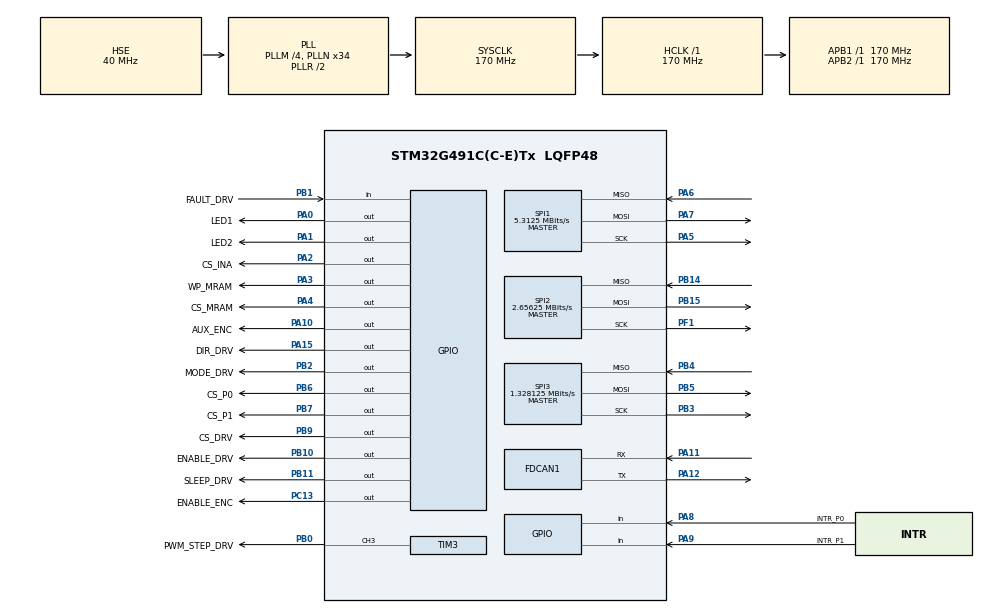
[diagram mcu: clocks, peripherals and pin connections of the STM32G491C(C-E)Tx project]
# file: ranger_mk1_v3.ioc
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FDCAN1.AutoRetransmission=ENABLE
FDCAN1.CalculateBaudRateNominal=1000000
FDCAN1.CalculateTimeBitNominal=1000
FDCAN1.CalculateTimeQuantumNominal=100.0
FDCAN1.ExtFiltersNbr=1
FDCAN1.NominalPrescaler=17
FDCAN1.NominalSyncJumpWidth=2
FDCAN1.NominalTimeSeg1=7
FDCAN1.NominalTimeSeg2=2
Mcu.Family=STM32G4
Mcu.Name=STM32G491C(C-E)Tx
Mcu.Package=LQFP48
NVIC.PriorityGroup=NVIC_PRIORITYGROUP_4
NVIC.TIM2_IRQn=true\:0\:0\:false\:false\:true\:true\:true\:true
PA0.GPIO_Label=LED1
PA0.PinState=GPIO_PIN_SET
PA0.Signal=GPIO_Output
PA1.GPIO_Label=LED2
PA1.PinState=GPIO_PIN_SET
PA1.Signal=GPIO_Output
PA10.GPIO_Label=AUX_ENC
PA10.Signal=GPIO_Output
PA11.Mode=FDCAN_Activate
PA11.Signal=FDCAN1_RX
PA12.Mode=FDCAN_Activate
PA12.Signal=FDCAN1_TX
PA13.Mode=Serial_Wire
PA13.Signal=SYS_JTMS-SWDIO
PA14.Mode=Serial_Wire
PA14.Signal=SYS_JTCK-SWCLK
PA15.GPIO_Label=DIR_DRV
PA15.PinState=GPIO_PIN_RESET
PA15.Signal=GPIO_Output
PA2.GPIO_Label=CS_INA
PA2.PinState=GPIO_PIN_SET
PA2.Signal=GPIO_Output
PA3.GPIO_Label=WP_MRAM
PA3.PinState=GPIO_PIN_SET
PA3.Signal=GPIO_Output
PA4.GPIO_Label=CS_MRAM
PA4.PinState=GPIO_PIN_SET
PA4.Signal=GPIO_Output
PA5.Mode=Full_Duplex_Master
PA5.Signal=SPI1_SCK
PA6.Mode=Full_Duplex_Master
PA6.Signal=SPI1_MISO
PA7.Mode=Full_Duplex_Master
PA7.Signal=SPI1_MOSI
PA8.GPIO_Label=INTR_P0
PA8.Signal=GPIO_Input
PA9.GPIO_Label=INTR_P1
PA9.Signal=GPIO_Input
PB0.GPIO_Label=PWM_STEP_DRV
PB0.Signal=S_TIM3_CH3
PB1.GPIO_Label=FAULT_DRV
PB1.Signal=GPIO_Input
PB10.GPIO_Label=ENABLE_DRV
PB10.Signal=GPIO_Output
PB11.GPIO_Label=SLEEP_DRV
PB11.Signal=GPIO_Output
PB14.Mode=Full_Duplex_Master
PB14.Signal=SPI2_MISO
PB15.Mode=Full_Duplex_Master
PB15.Signal=SPI2_MOSI
PB2.GPIO_Label=MODE_DRV
PB2.PinState=GPIO_PIN_SET
PB2.Signal=GPIO_Output
PB3.Mode=Full_Duplex_Master
PB3.Signal=SPI3_SCK
PB4.Mode=Full_Duplex_Master
PB4.Signal=SPI3_MISO
PB5.Mode=Full_Duplex_Master
PB5.Signal=SPI3_MOSI
PB6.GPIO_Label=CS_P0
PB6.PinState=GPIO_PIN_SET
PB6.Signal=GPIO_Output
PB7.GPIO_Label=CS_P1
PB7.PinState=GPIO_PIN_SET
PB7.Signal=GPIO_Output
PB9.GPIO_Label=CS_DRV
PB9.PinState=GPIO_PIN_SET
PB9.Signal=GPIO_Output
PC13.GPIO_Label=ENABLE_ENC
PC13.PinState=GPIO_PIN_SET
PC13.Signal=GPIO_Output
PF0-OSC_IN.Mode=HSE-External-Clock-Source
PF0-OSC_IN.Signal=RCC_OSC_IN
PF1-OSC_OUT.Mode=Full_Duplex_Master
PF1-OSC_OUT.Signal=SPI2_SCK
ProjectManager.HeapSize=0x200
ProjectManager.StackSize=0x400
ProjectManager.TargetToolchain=STM32CubeIDE
RCC.ADC12Freq_Value=170000000
RCC.ADC345Freq_Value=170000000
RCC.AHBFreq_Value=170000000
RCC.APB1Freq_Value=170000000
RCC.APB1TimFreq_Value=170000000
RCC.APB2Freq_Value=170000000
RCC.APB2TimFreq_Value=170000000
RCC.CortexFreq_Value=170000000
RCC.EXTERNAL_CLOCK_VALUE=12288000
RCC.HCLKFreq_Value=170000000
RCC.HSE_VALUE=40000000
RCC.HSI48_VALUE=48000000
RCC.HSI_VALUE=16000000
RCC.LSE_VALUE=32768
RCC.PLLM=RCC_PLLM_DIV4
RCC.PLLN=34
RCC.PLLSourceVirtual=RCC_PLLSOURCE_HSE
RCC.SYSCLKFreq_VALUE=170000000
RCC.SYSCLKSource=RCC_SYSCLKSOURCE_PLLCLK
RCC.VCOOutputFreq_Value=340000000
SH.S_TIM3_CH3.0=TIM3_CH3,PWM Generation3 CH3
SPI1.BaudRatePrescaler=SPI_BAUDRATEPRESCALER_32
SPI1.CalculateBaudRate=5.3125 MBits/s
SPI1.DataSize=SPI_DATASIZE_8BIT
SPI1.Direction=SPI_DIRECTION_2LINES
SPI1.Mode=SPI_MODE_MASTER
SPI1.VirtualType=VM_MASTER
SPI2.BaudRatePrescaler=SPI_BAUDRATEPRESCALER_64
SPI2.CLKPhase=SPI_PHASE_2EDGE
SPI2.CalculateBaudRate=2.65625 MBits/s
SPI2.DataSize=SPI_DATASIZE_8BIT
SPI2.Direction=SPI_DIRECTION_2LINES
SPI2.Mode=SPI_MODE_MASTER
SPI2.VirtualType=VM_MASTER
SPI3.BaudRatePrescaler=SPI_BAUDRATEPRESCALER_128
SPI3.CLKPhase=SPI_PHASE_2EDGE
SPI3.CalculateBaudRate=1.328125 MBits/s
SPI3.DataSize=SPI_DATASIZE_8BIT
SPI3.Direction=SPI_DIRECTION_2LINES
SPI3.Mode=SPI_MODE_MASTER
SPI3.VirtualType=VM_MASTER
TIM2.PeriodNoDither=4294967295
TIM2.Prescaler=0
TIM2.TIM_MasterOutputTrigger=TIM_TRGO_RESET
TIM3.AutoReloadPreload=TIM_AUTORELOAD_PRELOAD_ENABLE
TIM3.Channel-PWM\ Generation3\ CH3=TIM_CHANNEL_3
TIM3.OC3Preload_PWM=DISABLE
TIM3.PeriodNoDither=999
TIM3.Prescaler=169
TIM3.PulseNoDither_3=2
TIM3.TIM_MasterOutputTrigger=TIM_TRGO_OC3REF
VP_SYS_VS_DBSignals.Mode=DisableDeadBatterySignals
VP_TIM2_VS_ClockSourceITR.Mode=TriggerSource_ITR2
VP_TIM2_VS_ControllerModeClock.Mode=Clock Mode
VP_TIM3_VS_ClockSourceINT.Mode=Internal
board=custom

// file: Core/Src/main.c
/* USER CODE BEGIN Header */
/**
  ******************************************************************************
  * @file           : main.c
  * @brief          : Main program body
  ******************************************************************************
  */
/* USER CODE END Header */
#include "main.h"

/* USER CODE BEGIN Includes */
#include "ranger_app.h"
/* USER CODE END Includes */

FDCAN_HandleTypeDef hfdcan1;

SPI_HandleTypeDef hspi1;
SPI_HandleTypeDef hspi2;
SPI_HandleTypeDef hspi3;

TIM_HandleTypeDef htim2;
TIM_HandleTypeDef htim3;

void SystemClock_Config(void);
static void MX_GPIO_Init(void);
static void MX_FDCAN1_Init(void);
static void MX_SPI1_Init(void);
static void MX_SPI2_Init(void);
static void MX_TIM2_Init(void);
static void MX_TIM3_Init(void);
static void MX_SPI3_Init(void);

int main(void)
{

  /* USER CODE BEGIN 1 */
  SCB->VTOR = 0x08008000U;
  /* USER CODE END 1 */

  /* MCU Configuration--------------------------------------------------------*/

  /* Reset of all peripherals, Initializes the Flash interface and the Systick. */
  HAL_Init();

  /* Configure the system clock */
  SystemClock_Config();

  /* Initialize all configured peripherals */
  MX_GPIO_Init();
  MX_FDCAN1_Init();
  MX_SPI1_Init();
  MX_SPI2_Init();
  MX_TIM2_Init();
  MX_TIM3_Init();
  MX_SPI3_Init();
  /* USER CODE BEGIN 2 */
  HAL_Delay(100);
  ranger_app_init();
  /* USER CODE END 2 */

  /* Infinite loop */
  while (1)
  {

    /* USER CODE BEGIN 3 */
	ranger_app_tick();

  }
  /* USER CODE END 3 */
}

void SystemClock_Config(void)
{
  RCC_OscInitTypeDef RCC_OscInitStruct = {0};
  RCC_ClkInitTypeDef RCC_ClkInitStruct = {0};

  /** Configure the main internal regulator output voltage
  */
  HAL_PWREx_ControlVoltageScaling(PWR_REGULATOR_VOLTAGE_SCALE1_BOOST);

  /** Initializes the RCC Oscillators according to the specified parameters
  * in the RCC_OscInitTypeDef structure.
  */
  RCC_OscInitStruct.OscillatorType = RCC_OSCILLATORTYPE_HSE;
  RCC_OscInitStruct.HSEState = RCC_HSE_BYPASS;
  RCC_OscInitStruct.PLL.PLLState = RCC_PLL_ON;
  RCC_OscInitStruct.PLL.PLLSource = RCC_PLLSOURCE_HSE;
  RCC_OscInitStruct.PLL.PLLM = RCC_PLLM_DIV4;
  RCC_OscInitStruct.PLL.PLLN = 34;
  RCC_OscInitStruct.PLL.PLLP = RCC_PLLP_DIV2;
  RCC_OscInitStruct.PLL.PLLQ = RCC_PLLQ_DIV2;
  RCC_OscInitStruct.PLL.PLLR = RCC_PLLR_DIV2;
  if (HAL_RCC_OscConfig(&RCC_OscInitStruct) != HAL_OK)
  {
    Error_Handler();
  }

  /** Initializes the CPU, AHB and APB buses clocks
  */
  RCC_ClkInitStruct.ClockType = RCC_CLOCKTYPE_HCLK|RCC_CLOCKTYPE_SYSCLK
                              |RCC_CLOCKTYPE_PCLK1|RCC_CLOCKTYPE_PCLK2;
  RCC_ClkInitStruct.SYSCLKSource = RCC_SYSCLKSOURCE_PLLCLK;
  RCC_ClkInitStruct.AHBCLKDivider = RCC_SYSCLK_DIV1;
  RCC_ClkInitStruct.APB1CLKDivider = RCC_HCLK_DIV1;
  RCC_ClkInitStruct.APB2CLKDivider = RCC_HCLK_DIV1;

  if (HAL_RCC_ClockConfig(&RCC_ClkInitStruct, FLASH_LATENCY_4) != HAL_OK)
  {
    Error_Handler();
  }
}

static void MX_FDCAN1_Init(void)
{

  hfdcan1.Instance = FDCAN1;
  hfdcan1.Init.ClockDivider = FDCAN_CLOCK_DIV1;
  hfdcan1.Init.FrameFormat = FDCAN_FRAME_CLASSIC;
  hfdcan1.Init.Mode = FDCAN_MODE_NORMAL;
  hfdcan1.Init.AutoRetransmission = ENABLE;
  hfdcan1.Init.TransmitPause = DISABLE;
  hfdcan1.Init.ProtocolException = DISABLE;
  hfdcan1.Init.NominalPrescaler = 17;
  hfdcan1.Init.NominalSyncJumpWidth = 2;
  hfdcan1.Init.NominalTimeSeg1 = 7;
  hfdcan1.Init.NominalTimeSeg2 = 2;
  hfdcan1.Init.DataPrescaler = 1;
  hfdcan1.Init.DataSyncJumpWidth = 1;
  hfdcan1.Init.DataTimeSeg1 = 1;
  hfdcan1.Init.DataTimeSeg2 = 1;
  hfdcan1.Init.StdFiltersNbr = 0;
  hfdcan1.Init.ExtFiltersNbr = 1;
  hfdcan1.Init.TxFifoQueueMode = FDCAN_TX_FIFO_OPERATION;
  if (HAL_FDCAN_Init(&hfdcan1) != HAL_OK)
  {
    Error_Handler();
  }

}

static void MX_SPI1_Init(void)
{

  /* SPI1 parameter configuration*/
  hspi1.Instance = SPI1;
  hspi1.Init.Mode = SPI_MODE_MASTER;
  hspi1.Init.Direction = SPI_DIRECTION_2LINES;
  hspi1.Init.DataSize = SPI_DATASIZE_8BIT;
  hspi1.Init.CLKPolarity = SPI_POLARITY_LOW;
  hspi1.Init.CLKPhase = SPI_PHASE_1EDGE;
  hspi1.Init.NSS = SPI_NSS_SOFT;
  hspi1.Init.BaudRatePrescaler = SPI_BAUDRATEPRESCALER_32;
  hspi1.Init.FirstBit = SPI_FIRSTBIT_MSB;
  hspi1.Init.TIMode = SPI_TIMODE_DISABLE;
  hspi1.Init.CRCCalculation = SPI_CRCCALCULATION_DISABLE;
  hspi1.Init.CRCPolynomial = 7;
  hspi1.Init.CRCLength = SPI_CRC_LENGTH_DATASIZE;
  hspi1.Init.NSSPMode = SPI_NSS_PULSE_ENABLE;
  if (HAL_SPI_Init(&hspi1) != HAL_OK)
  {
    Error_Handler();
  }

}

static void MX_SPI2_Init(void)
{

  /* SPI2 parameter configuration*/
  hspi2.Instance = SPI2;
  hspi2.Init.Mode = SPI_MODE_MASTER;
  hspi2.Init.Direction = SPI_DIRECTION_2LINES;
  hspi2.Init.DataSize = SPI_DATASIZE_8BIT;
  hspi2.Init.CLKPolarity = SPI_POLARITY_LOW;
  hspi2.Init.CLKPhase = SPI_PHASE_2EDGE;
  hspi2.Init.NSS = SPI_NSS_SOFT;
  hspi2.Init.BaudRatePrescaler = SPI_BAUDRATEPRESCALER_64;
  hspi2.Init.FirstBit = SPI_FIRSTBIT_MSB;
  hspi2.Init.TIMode = SPI_TIMODE_DISABLE;
  hspi2.Init.CRCCalculation = SPI_CRCCALCULATION_DISABLE;
  hspi2.Init.CRCPolynomial = 7;
  hspi2.Init.CRCLength = SPI_CRC_LENGTH_DATASIZE;
  hspi2.Init.NSSPMode = SPI_NSS_PULSE_DISABLE;
  if (HAL_SPI_Init(&hspi2) != HAL_OK)
  {
    Error_Handler();
  }

}

static void MX_SPI3_Init(void)
{

  /* SPI3 parameter configuration*/
  hspi3.Instance = SPI3;
  hspi3.Init.Mode = SPI_MODE_MASTER;
  hspi3.Init.Direction = SPI_DIRECTION_2LINES;
  hspi3.Init.DataSize = SPI_DATASIZE_8BIT;
  hspi3.Init.CLKPolarity = SPI_POLARITY_LOW;
  hspi3.Init.CLKPhase = SPI_PHASE_2EDGE;
  hspi3.Init.NSS = SPI_NSS_SOFT;
  hspi3.Init.BaudRatePrescaler = SPI_BAUDRATEPRESCALER_128;
  hspi3.Init.FirstBit = SPI_FIRSTBIT_MSB;
  hspi3.Init.TIMode = SPI_TIMODE_DISABLE;
  hspi3.Init.CRCCalculation = SPI_CRCCALCULATION_DISABLE;
  hspi3.Init.CRCPolynomial = 7;
  hspi3.Init.CRCLength = SPI_CRC_LENGTH_DATASIZE;
  hspi3.Init.NSSPMode = SPI_NSS_PULSE_DISABLE;
  if (HAL_SPI_Init(&hspi3) != HAL_OK)
  {
    Error_Handler();
  }

}

static void MX_TIM2_Init(void)
{

  TIM_SlaveConfigTypeDef sSlaveConfig = {0};
  TIM_MasterConfigTypeDef sMasterConfig = {0};

  htim2.Instance = TIM2;
  htim2.Init.Prescaler = 0;
  htim2.Init.CounterMode = TIM_COUNTERMODE_UP;
  htim2.Init.Period = 4294967295;
  htim2.Init.ClockDivision = TIM_CLOCKDIVISION_DIV1;
  htim2.Init.AutoReloadPreload = TIM_AUTORELOAD_PRELOAD_DISABLE;
  if (HAL_TIM_Base_Init(&htim2) != HAL_OK)
  {
    Error_Handler();
  }
  sSlaveConfig.SlaveMode = TIM_SLAVEMODE_EXTERNAL1;
  sSlaveConfig.InputTrigger = TIM_TS_ITR2;
  if (HAL_TIM_SlaveConfigSynchro(&htim2, &sSlaveConfig) != HAL_OK)
  {
    Error_Handler();
  }
  sMasterConfig.MasterOutputTrigger = TIM_TRGO_RESET;
  sMasterConfig.MasterSlaveMode = TIM_MASTERSLAVEMODE_DISABLE;
  if (HAL_TIMEx_MasterConfigSynchronization(&htim2, &sMasterConfig) != HAL_OK)
  {
    Error_Handler();
  }

}

static void MX_TIM3_Init(void)
{

  TIM_ClockConfigTypeDef sClockSourceConfig = {0};
  TIM_MasterConfigTypeDef sMasterConfig = {0};
  TIM_OC_InitTypeDef sConfigOC = {0};

  htim3.Instance = TIM3;
  htim3.Init.Prescaler = 169;
  htim3.Init.CounterMode = TIM_COUNTERMODE_UP;
  htim3.Init.Period = 999;
  htim3.Init.ClockDivision = TIM_CLOCKDIVISION_DIV1;
  htim3.Init.AutoReloadPreload = TIM_AUTORELOAD_PRELOAD_ENABLE;
  if (HAL_TIM_Base_Init(&htim3) != HAL_OK)
  {
    Error_Handler();
  }
  sClockSourceConfig.ClockSource = TIM_CLOCKSOURCE_INTERNAL;
  if (HAL_TIM_ConfigClockSource(&htim3, &sClockSourceConfig) != HAL_OK)
  {
    Error_Handler();
  }
  if (HAL_TIM_PWM_Init(&htim3) != HAL_OK)
  {
    Error_Handler();
  }
  sMasterConfig.MasterOutputTrigger = TIM_TRGO_OC3REF;
  sMasterConfig.MasterSlaveMode = TIM_MASTERSLAVEMODE_DISABLE;
  if (HAL_TIMEx_MasterConfigSynchronization(&htim3, &sMasterConfig) != HAL_OK)
  {
    Error_Handler();
  }
  sConfigOC.OCMode = TIM_OCMODE_PWM1;
  sConfigOC.Pulse = 2;
  sConfigOC.OCPolarity = TIM_OCPOLARITY_HIGH;
  sConfigOC.OCFastMode = TIM_OCFAST_DISABLE;
  if (HAL_TIM_PWM_ConfigChannel(&htim3, &sConfigOC, TIM_CHANNEL_3) != HAL_OK)
  {
    Error_Handler();
  }
  __HAL_TIM_DISABLE_OCxPRELOAD(&htim3, TIM_CHANNEL_3);
  HAL_TIM_MspPostInit(&htim3);

}

static void MX_GPIO_Init(void)
{
  GPIO_InitTypeDef GPIO_InitStruct = {0};

  /* GPIO Ports Clock Enable */
  __HAL_RCC_GPIOC_CLK_ENABLE();
  __HAL_RCC_GPIOF_CLK_ENABLE();
  __HAL_RCC_GPIOA_CLK_ENABLE();
  __HAL_RCC_GPIOB_CLK_ENABLE();

  /*Configure GPIO pin Output Level */
  HAL_GPIO_WritePin(ENABLE_ENC_GPIO_Port, ENABLE_ENC_Pin, GPIO_PIN_SET);

  /*Configure GPIO pin Output Level */
  HAL_GPIO_WritePin(GPIOA, LED1_Pin|LED2_Pin|CS_INA_Pin|WP_MRAM_Pin
                          |CS_MRAM_Pin, GPIO_PIN_SET);

  /*Configure GPIO pin Output Level */
  HAL_GPIO_WritePin(GPIOB, MODE_DRV_Pin|CS_P0_Pin|CS_P1_Pin|CS_DRV_Pin, GPIO_PIN_SET);

  /*Configure GPIO pin Output Level */
  HAL_GPIO_WritePin(GPIOB, ENABLE_DRV_Pin|SLEEP_DRV_Pin, GPIO_PIN_RESET);

  /*Configure GPIO pin Output Level */
  HAL_GPIO_WritePin(GPIOA, AUX_ENC_Pin|DIR_DRV_Pin, GPIO_PIN_RESET);

  /*Configure GPIO pin : ENABLE_ENC_Pin */
  GPIO_InitStruct.Pin = ENABLE_ENC_Pin;
  GPIO_InitStruct.Mode = GPIO_MODE_OUTPUT_PP;
  GPIO_InitStruct.Pull = GPIO_NOPULL;
  GPIO_InitStruct.Speed = GPIO_SPEED_FREQ_LOW;
  HAL_GPIO_Init(ENABLE_ENC_GPIO_Port, &GPIO_InitStruct);

  /*Configure GPIO pins : LED1_Pin LED2_Pin CS_INA_Pin WP_MRAM_Pin
                           CS_MRAM_Pin AUX_ENC_Pin DIR_DRV_Pin */
  GPIO_InitStruct.Pin = LED1_Pin|LED2_Pin|CS_INA_Pin|WP_MRAM_Pin
                          |CS_MRAM_Pin|AUX_ENC_Pin|DIR_DRV_Pin;
  GPIO_InitStruct.Mode = GPIO_MODE_OUTPUT_PP;
  GPIO_InitStruct.Pull = GPIO_NOPULL;
  GPIO_InitStruct.Speed = GPIO_SPEED_FREQ_LOW;
  HAL_GPIO_Init(GPIOA, &GPIO_InitStruct);

  /*Configure GPIO pin : FAULT_DRV_Pin */
  GPIO_InitStruct.Pin = FAULT_DRV_Pin;
  GPIO_InitStruct.Mode = GPIO_MODE_INPUT;
  GPIO_InitStruct.Pull = GPIO_NOPULL;
  HAL_GPIO_Init(FAULT_DRV_GPIO_Port, &GPIO_InitStruct);

  /*Configure GPIO pins : MODE_DRV_Pin ENABLE_DRV_Pin SLEEP_DRV_Pin CS_P0_Pin
                           CS_P1_Pin CS_DRV_Pin */
  GPIO_InitStruct.Pin = MODE_DRV_Pin|ENABLE_DRV_Pin|SLEEP_DRV_Pin|CS_P0_Pin
                          |CS_P1_Pin|CS_DRV_Pin;
  GPIO_InitStruct.Mode = GPIO_MODE_OUTPUT_PP;
  GPIO_InitStruct.Pull = GPIO_NOPULL;
  GPIO_InitStruct.Speed = GPIO_SPEED_FREQ_LOW;
  HAL_GPIO_Init(GPIOB, &GPIO_InitStruct);

  /*Configure GPIO pins : INTR_P0_Pin INTR_P1_Pin */
  GPIO_InitStruct.Pin = INTR_P0_Pin|INTR_P1_Pin;
  GPIO_InitStruct.Mode = GPIO_MODE_INPUT;
  GPIO_InitStruct.Pull = GPIO_NOPULL;
  HAL_GPIO_Init(GPIOA, &GPIO_InitStruct);

}

void Error_Handler(void)
{
  __disable_irq();
  while (1)
  {
  }
}
